# CC1314R10 register map
File version: 1.0
CPU: CM33 1.0, other endian, MPU, FPU, 3 interrupt priority bits
Registers are 32-bit, read-write, reset 0x0 unless marked. A register's access mark holds for its fields unless they carry their own. Offsets are from the block's base; [hi:lo] are bit positions; {n}, {i} and the like mark numbered series.

## AUX_SMPH — AUX Semaphore (AUX_SMPH) provides hardware means to share modules in AUX safely between CPUs based on resource ownership. AUX_SMPH operates at AUX bus rate.
Base 0x400C8000
{0x0+4i} SMPH{i} reset 0x1 (i=0..7) — Semaphore {i}
  [0] STAT — [0:0] Request or release of semaphore. Request by read: 0: Semaphore not available. 1: Semaphore granted. Release by write: 0: Do not use. 1: Release semaphore.
0x20 AUTOTAKE — Auto Take Sticky Request for Single Semaphore.
  [2:0] SMPH_ID — [2:0] Write the semaphore ID,0x0-0x7, to SMPH_ID to request this semaphore until it is granted. When semaphore SMPH_ID is granted, event AUX_EVCTL:EVSTAT3.AUX_SMPH_AUTOTAKE_DONE becomes 1. The event becomes 0 when software releases the semaphore or writes a new value to SMPH_ID. To avoid corrupted semaphores: - Usage of this functionality must be restricted to one CPU core. - Software must wait until AUX_EVCTL:EVSTAT3.AUX_SMPH_AUTOTAKE_DONE is 1 before it writes a new value to SMPH_ID.

## PKA_INT — Integrated module which includes the PKA K
Base 0x58027000
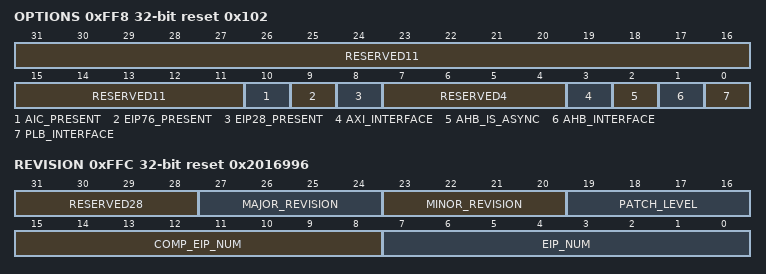
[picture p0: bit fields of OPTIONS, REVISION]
0xFF8 OPTIONS reset 0x102 — PKA Options register
  [31:11] RESERVED11 ro — [31:11] Ignore on read
  [10] AIC_PRESENT ro — [10:10] When set to '1', indicates that an EIP201 AIC is included in the EIP150
  [9] EIP76_PRESENT ro — [9:9] When set to '1', indicates that the EIP76 TRNG is included in the EIP150
  [8] EIP28_PRESENT ro — [8:8] When set to '1', indicates that the EIP28 PKA is included in the EIP150
  [7:4] RESERVED4 ro — [7:4] Ignore on read
  [3] AXI_INTERFACE ro — [3:3] When set to '1', indicates that the EIP150 is equipped with a AXI interface
  [2] AHB_IS_ASYNC ro — [2:2] When set to '1', indicates that AHB interface is asynchronous Only applicable when AHB_INTERFACE is 1
  [1] AHB_INTERFACE — [1:1] When set to '1', indicates that the EIP150 is equipped with a AHB interface
  [0] PLB_INTERFACE — [0:0] When set to '1', indicates that the EIP150 is equipped with a PLB interface
0xFFC REVISION reset 0x2016996 — PKA hardware revision register This register allows the host access to the hardware revision number of the PKA engine for software driver matching and diagnostic purposes. It is always located at the highest address in the access space of the module and contains an encoding of the EIP number (with its complement as signature) for recognition of the hardware module.
  [31:28] RESERVED28 ro — [31:28] These bits should be ignored on read
  [27:24] MAJOR_REVISION ro — [27:24] These bits encode the major version number for this module
  [23:20] MINOR_REVISION ro — [23:20] These bits encode the minor version number for this module
  [19:16] PATCH_LEVEL ro — [19:16] These bits encode the hardware patch level for this module they start at value 0 on the first release
  [15:8] COMP_EIP_NUM ro — [15:8] These bits simply contain the complement of bits [7:0], used by a driver to ascertain that the EIP150 revision register is indeed read
  [7:0] EIP_NUM ro — [7:0] These bits encode the AuthenTec EIP number for the EIP150

## SRAM_MMR — General Purpose RAM
Base 0x58035000
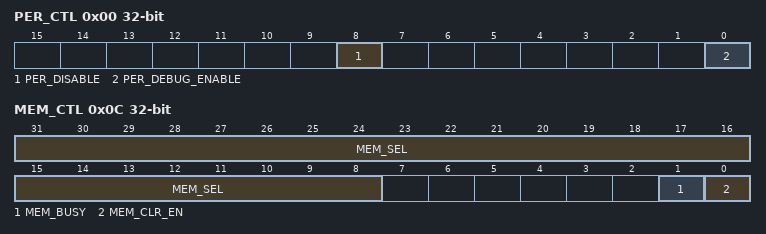
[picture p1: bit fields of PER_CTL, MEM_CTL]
0x00 PER_CTL — Parity Error Control Parity error check controls
  [8] PER_DISABLE — [8:8] Parity Status Disable 0: A parity error will update PER_CHK.PER_ADDR field 1: Parity error does not update PER_CHK.PER_ADDR field
  [0] PER_DEBUG_ENABLE — [0:0] Parity Error Debug Enable 0: Normal operation 1: An address offset can be written to PER_DBG.PER_DEBUG_ADDR and parity errors will be generated on reads from within this offset
0x04 PER_CHK — Parity Error Check Parity error check results
  [23:0] PER_ADDR ro — [23:0] Parity Error Address Offset Returns the last address offset which resulted in a parity error during an SRAM read. The address offset returned is always the word-aligned address that contains the location with the parity error. For parity faults on non word-aligned accesses, CPU_SCS:BFAR.ADDRESS will hold the address of the location that resulted in parity error.
0x08 PER_DBG — Parity Error Debug Parity error check debug address setting
  [23:0] PER_DEBUG_ADDR — [23:0] Debug Parity Error Address Offset When PER_CTL.PER_DEBUG is 1, this field is used to set a parity debug address offset. The address offset must be a word-aligned address. Writes within this address offset will force incorrect parity bits to be stored together with the data written. The following reads within this same address offset will thus result in parity errors to be generated.
0x0C MEM_CTL — Memory Control Controls memory initialization
  [31:8] MEM_SEL — [31:8] Memory Instance Select This field is used to enable/disable initialization of each SRAM instance when triggered using MEM_CTL.MEM_CLR_EN. Each bit corresponds to the respective SRAM instance. bit[x]: 0: Initialization of instance x is disabled 1: Initialization of instance x is enabled
  [1] MEM_BUSY ro — [1:1] Memory Busy status 0: Memory accepts transfers 1: Memory controller is busy during initialization. Read and write transfers are not performed.
  [0] MEM_CLR_EN — [0:0] Memory Contents Initialization enable Writing 1 to MEM_CLR_EN will start memory initialization. The contents of all byte locations will be initialized to 0x00. MEM_BUSY will be 1 until memory initialization has completed.
0x10 MEM_STA — Memory Status Controls memory initialization
  [31:8] MEM_STA ro — [31:8] Memory Instance Status This field gives the current status of each SRAM instance. When an instance is being initialized the corresponding bit is set to 1, 0 otherwise. bit[x]: 0 : Instance x is in normal mode 1 : Instance x is getting initialized
